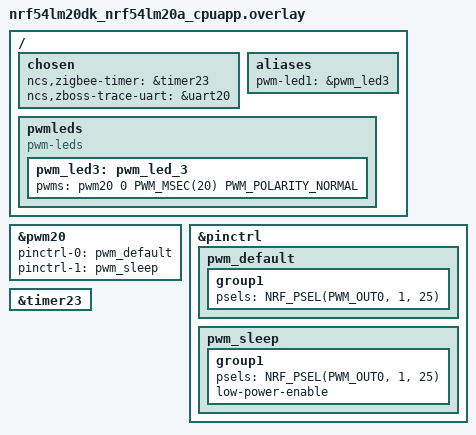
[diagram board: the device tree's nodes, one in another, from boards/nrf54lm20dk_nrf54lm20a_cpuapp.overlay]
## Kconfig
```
#
# Copyright (c) 2026 Nordic Semiconductor ASA
#
# SPDX-License-Identifier: LicenseRef-Nordic-5-Clause
#

# Sample configuration used for Thread networking
if OPENTHREAD

choice OPENTHREAD_NORDIC_LIBRARY_CONFIGURATION
	default OPENTHREAD_NORDIC_LIBRARY_FTD
endchoice

choice OPENTHREAD_DEVICE_TYPE
	default OPENTHREAD_FTD
endchoice

endif # OPENTHREAD

if CHIP
source "$(ZEPHYR_CONNECTEDHOMEIP_MODULE_DIR)/config/nrfconnect/chip-module/Kconfig.features"
source "$(ZEPHYR_CONNECTEDHOMEIP_MODULE_DIR)/config/nrfconnect/chip-module/Kconfig.defaults"
source "$(ZEPHYR_NRF_MODULE_DIR)/samples/matter/common/src/Kconfig"
endif

source "Kconfig.zephyr"
```

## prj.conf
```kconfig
#
# Copyright (c) 2024 Nordic Semiconductor ASA
#
# SPDX-License-Identifier: LicenseRef-Nordic-5-Clause
#

CONFIG_NCS_SAMPLES_DEFAULTS=y

CONFIG_UART_INTERRUPT_DRIVEN=y
CONFIG_SERIAL=y
CONFIG_GPIO=y
CONFIG_PWM=y

# Make sure printk is not printing to the UART console
CONFIG_CONSOLE=y
CONFIG_UART_CONSOLE=y

CONFIG_HEAP_MEM_POOL_SIZE=2048
CONFIG_MAIN_THREAD_PRIORITY=7

CONFIG_ZIGBEE_ADD_ON=y
CONFIG_ZIGBEE_APP_UTILS=y
CONFIG_ZIGBEE_ROLE_ROUTER=y

# Enable DK LED and Buttons library
CONFIG_DK_LIBRARY=y

# This example requires more workqueue stack
CONFIG_SYSTEM_WORKQUEUE_STACK_SIZE=2048

# Networking
CONFIG_NET_IPV6=n
CONFIG_NET_IP_ADDR_CHECK=n
CONFIG_NET_UDP=n

# Scene extension
CONFIG_ZIGBEE_SCENES=y

CONFIG_THREAD_MONITOR=y
CONFIG_THREAD_NAME=y
CONFIG_KERNEL_SHELL=y
```

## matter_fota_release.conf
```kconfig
#
# Copyright (c) 2026 Nordic Semiconductor ASA
#
# SPDX-License-Identifier: LicenseRef-Nordic-5-Clause
#
# Debug configuration for combined Zigbee + Matter + Thread (PoC)
# Includes logging, console, and debug features

#######################
# Release Optimizations
#######################

# Disable all debug features
CONFIG_USE_SEGGER_RTT=n
CONFIG_SHELL=n
CONFIG_OPENTHREAD_SHELL=n
CONFIG_CONSOLE=n
CONFIG_UART_CONSOLE=n
CONFIG_SERIAL=n
CONFIG_UART_INTERRUPT_DRIVEN=n
CONFIG_LOG=n
CONFIG_LOG_MODE_MINIMAL=n
CONFIG_ASSERT_VERBOSE=n
CONFIG_ASSERT_NO_FILE_INFO=y
CONFIG_PRINTK=n
CONFIG_PRINTK_SYNC=n
CONFIG_BOOT_BANNER=n

# Enable LTO to decrease the flash usage
CONFIG_LTO=y
CONFIG_ISR_TABLES_LOCAL_DECLARATION=y

# Additional size optimizations
CONFIG_SIZE_OPTIMIZATIONS=y
CONFIG_COMPILER_OPT="-Os"
```

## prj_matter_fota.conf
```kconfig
#
# Copyright (c) 2026 Nordic Semiconductor ASA
#
# SPDX-License-Identifier: LicenseRef-Nordic-5-Clause
#
# Debug configuration for combined Zigbee + Matter + Thread (PoC)
# Includes logging, console, and debug features

# Base sample configs
CONFIG_NCS_SAMPLES_DEFAULTS=y

CONFIG_UART_INTERRUPT_DRIVEN=y
CONFIG_SERIAL=y
CONFIG_GPIO=y
CONFIG_PWM=y

# Console
CONFIG_CONSOLE=y
CONFIG_UART_CONSOLE=y

# CONFIG_HEAP_MEM_POOL_SIZE=4096
CONFIG_MAIN_THREAD_PRIORITY=7

#######################
# Zigbee Configuration
#######################

CONFIG_ZIGBEE_ADD_ON=y
CONFIG_ZIGBEE_APP_UTILS=y
# Show Zigbee init/recovery logs (Device first start, network steering recovery).
CONFIG_ZIGBEE_APP_UTILS_LOG_LEVEL_INF=y
CONFIG_ZIGBEE_ROLE_ROUTER=y

# Scene extension
CONFIG_ZIGBEE_SCENES=y

# Enable DK LED and Buttons library
CONFIG_DK_LIBRARY=y

# This example requires more workqueue stack
CONFIG_SYSTEM_WORKQUEUE_STACK_SIZE=2048

CONFIG_ZBOSS_OSIF_LOG_LEVEL_INF=y

#######################
# Zigbee FOTA Configuration
#######################

# FIXME: Disabled Zigbee FOTA for initial development
# # Enable Zigbee FOTA library
# CONFIG_ZIGBEE_FOTA=y
# CONFIG_ZIGBEE_FOTA_HW_VERSION=52
# CONFIG_ZIGBEE_FOTA_ENDPOINT=5
# CONFIG_MCUBOOT_IMGTOOL_SIGN_VERSION="1.0.0"
# CONFIG_ZIGBEE_FOTA_COMMENT="light_bulb_matter"

# # Ensure an MCUboot-compatible binary is generated.
# CONFIG_IMG_MANAGER=y
# CONFIG_STREAM_FLASH=y
# CONFIG_DFU_TARGET_MCUBOOT=y
# CONFIG_IMG_ERASE_PROGRESSIVELY=y
# CONFIG_ZIGBEE_FOTA_PROGRESS_EVT=y

# # Increase the number of RX buffers for FOTA
# CONFIG_NRF_802154_RX_BUFFERS=32

#######################
# Matter Configuration
#######################

# Enable CHIP (Matter)
CONFIG_CHIP=y
CONFIG_CHIP_PROJECT_CONFIG="include/chip_project_config.h"
CONFIG_CHIP_DEVICE_PRODUCT_NAME="Matter Zigbee Light Bulb"

# Configure ZAP file
CONFIG_NCS_SAMPLE_MATTER_ZAP_FILE_PATH="${APPLICATION_CONFIG_DIR}/src/matter_zap/light_bulb.zap"

# 32773 == 0x8005 (example lighting-app)
CONFIG_CHIP_DEVICE_PRODUCT_ID=32773
CONFIG_STD_CPP17=y

# Enable Matter pairing automatically on application start.
CONFIG_CHIP_ENABLE_PAIRING_AUTOSTART=y

# Enable Matter extended announcement and increase duration to 1 hour.
CONFIG_CHIP_BLE_EXT_ADVERTISING=y
CONFIG_CHIP_BLE_ADVERTISING_DURATION=60

CONFIG_BT_DEVICE_NAME="MatterZigbee"

# Other settings
CONFIG_THREAD_NAME=y
CONFIG_MPU_STACK_GUARD=y
CONFIG_RESET_ON_FATAL_ERROR=n

# Reduce application size
CONFIG_USE_SEGGER_RTT=n

# FIXME: Disabled Factory Data feature for initial development
# CONFIG_CHIP_FACTORY_DATA_NONE=y

# FIXME: Disabled Matter OTA for initial development
CONFIG_CHIP_OTA_REQUESTOR=n
CONFIG_CHIP_BOOTLOADER_MCUBOOT=n
CONFIG_CHIP_BOOTLOADER_NONE=y

# Increase system workqueue stack for combined protocols (with Thread)
CONFIG_SYSTEM_WORKQUEUE_STACK_SIZE=6144

# Libc malloc arena required for Zigbee + Matter coexistence.
# - 0: no libc heap -> Matter init fails (malloc/calloc used during init).
# - -1: "all remaining RAM" -> on this build the computed heap extends past
#   valid RAM and triggers a precise data bus fault in sys_heap_init().
# - Positive value: static BSS heap of that size -> valid heap, no fault.
# Matter uses CHIP_MALLOC_SYS_HEAP for its own allocations; this arena
# covers libc malloc() used elsewhere (init, Zephyr, Zigbee, etc.).
CONFIG_COMMON_LIBC_MALLOC_ARENA_SIZE=-1

## PoC Configuration ##
# Note: This configuration links all three stacks (Zigbee, Thread, Matter) for memory estimation
# It will have runtime conflicts as Zigbee and Thread cannot share 802.15.4 radio simultaneously
# This is intentional - goal is to measure maximum memory footprint

# Keep Matter shell disabled to avoid getopt conflicts
CONFIG_CHIP_LIB_SHELL=n
CONFIG_NCS_SAMPLE_MATTER_TEST_SHELL=n

# Larger settings partition for Zigbee + Matter
CONFIG_PM_PARTITION_SIZE_SETTINGS_STORAGE=0x8000

# Enable for OpenThread logging
# UNCOMENT TO SEE LOGS FROM OPENTHREAD
# CONFIG_LOG_MODE_DEFERRED=y
# CONFIG_OPENTHREAD_DEBUG=y
# CONFIG_OPENTHREAD_LOG_LEVEL_DEBG=y
# CONFIG_LOG_BUFFER_SIZE=81920
# CONFIG_SHELL=y
# CONFIG_OPENTHREAD_SHELL=y

# Dispatcher 
CONFIG_NRF_802154_CALLBACKS_DISPATCHER=y

# We need it to disable ZBOSS thread
CONFIG_ZIGBEE_DEBUG_FUNCTIONS=y

# Must be a preemptible priority (0–15), not cooperative (-1). With -1, ZBOSS is
# coop priority -1 and is outranked by MPSL Work (prio -8), so it never runs.
# State 128 = _THREAD_QUEUED (runnable); ZBOSS stays queued and never gets CPU.
CONFIG_ZBOSS_DEFAULT_THREAD_PRIORITY=1
CONFIG_ZBOSS_DEFAULT_THREAD_STACK_SIZE=6144

# Switch to internal 802.15.4 radio source to fetch required changes.
CONFIG_NRF_802154_SOURCE_INTERNAL=y
```

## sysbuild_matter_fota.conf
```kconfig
#
# Copyright (c) 2026 Nordic Semiconductor ASA
#
# SPDX-License-Identifier: LicenseRef-Nordic-5-Clause
#

# Enable Matter support in sysbuild
SB_CONFIG_MATTER=y
SB_CONFIG_MATTER_FACTORY_DATA_GENERATE=y

# MCUBoot configuration
# SB_CONFIG_PM_OVERRIDE_EXTERNAL_DRIVER_CHECK=n
# SB_CONFIG_PM_EXTERNAL_FLASH_MCUBOOT_SECONDARY=n

SB_CONFIG_PARTITION_MANAGER=n

SB_CONFIG_MCUBOOT_MODE_OVERWRITE_ONLY=y
SB_CONFIG_MCUBOOT_COMPRESSED_IMAGE_SUPPORT=y
```

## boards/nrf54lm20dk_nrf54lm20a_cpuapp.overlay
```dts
/*
 * Copyright (c) 2025 Nordic Semiconductor ASA
 *
 * SPDX-License-Identifier: LicenseRef-Nordic-5-Clause
 */

#include <nrf54lm20_matter_zigbee_combined_partitions.dtsi>

/ {
	chosen {
		ncs,zigbee-timer = &timer23;
		ncs,zboss-trace-uart = &uart20;
	};

	aliases {
		/* Configure PWM module for led1 (LED2 on the board) */
		pwm-led1 = &pwm_led3;
	};

	pwmleds {
		compatible = "pwm-leds";
		pwm_led3: pwm_led_3 {
			pwms = <&pwm20 0 PWM_MSEC(20) PWM_POLARITY_NORMAL>;
		};
	};
};


&pwm20 {
	status = "okay";
	pinctrl-0 = <&pwm_default>;
	pinctrl-1 = <&pwm_sleep>;
	pinctrl-names = "default", "sleep";
};

&pinctrl {
	pwm_default: pwm_default {
		group1 {
			psels = <NRF_PSEL(PWM_OUT0, 1, 25)>;
		};
	};
	pwm_sleep: pwm_sleep {
		group1 {
			psels = <NRF_PSEL(PWM_OUT0, 1, 25)>;
			low-power-enable;
		};
	};
};

&timer23 {
	status = "okay";
};
```

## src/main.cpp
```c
/*
 * Copyright (c) 2024 Nordic Semiconductor ASA
 *
 * SPDX-License-Identifier: LicenseRef-Nordic-5-Clause
 */

/** @file
 *
 * @brief Simple Zigbee light bulb implementation.
 */

#include "app_task_zigbee.h"

#ifdef CONFIG_CHIP

#include "app_task.h"
#include <app/matter_event_handler.h>
#include <nrf_802154_callbacks_dispatcher.h>
#include <openthread.h>

extern "C" {
#include <zb_nrf_platform.h>
}

#include <zephyr/logging/log.h>

LOG_MODULE_REGISTER(app, CONFIG_CHIP_APP_LOG_LEVEL);

/* Zephyr thread stack size and priority */
#define ZIGBEE_THREAD_STACK_SIZE 2048
#define ZIGBEE_THREAD_PRIORITY 3
#define MATTER_THREAD_STACK_SIZE 3072
#define MATTER_THREAD_PRIORITY 3

namespace {

void zigbee_thread_fn() { ZigbeeStart(); }
void matter_thread_fn() { AppTask::Instance().StartApp(); }

K_THREAD_DEFINE(zigbee_thread_id, ZIGBEE_THREAD_STACK_SIZE, zigbee_thread_fn,
                NULL, NULL, NULL, ZIGBEE_THREAD_PRIORITY, 0, 0);

K_THREAD_DEFINE(matter_thread_id, MATTER_THREAD_STACK_SIZE, matter_thread_fn,
                NULL, NULL, NULL, MATTER_THREAD_PRIORITY, 0, 0);

void switch_to_thread_radio(void) {
  k_thread_abort(zigbee_thread_id);
  zigbee_deinit();
  int ret = nrf_802154_callbacks_dispatcher_switch("openthread");
  if (ret != 0) {
    LOG_ERR("Failed to switch 802.15.4 radio to Thread: %d", ret);
  }
}

void matter_zigbee_event_handler(
    const chip::DeviceLayer::ChipDeviceEvent *event, intptr_t arg) {
  switch (event->Type) {
  case chip::DeviceLayer::DeviceEventType::kSecureSessionEstablished:
    /* Switch to Thread Radio and disable Zigbee Stack*/
    if (!chip::DeviceLayer::ThreadStackMgr().IsThreadAttached()) {
      switch_to_thread_radio();
    }
    break;
  case chip::DeviceLayer::DeviceEventType::kFactoryReset:
    /* Remove also the zigbee stack data */
    zigbee_pibcache_pan_id_clear();
  default:
    break;
  }
}
} // namespace

#endif

int main(void) {

#ifdef CONFIG_CHIP

  int ret = nrf_802154_callbacks_dispatcher_switch("zigbee");
  if (ret != 0) {
    LOG_ERR("Failed to switch 802.15.4 radio to Zigbee: %d", ret);
  }

  // int ret = nrf_802154_callbacks_dispatcher_switch("openthread");
  // if (ret != 0) {
  //   LOG_ERR("Failed to switch 802.15.4 radio to Zigbee: %d", ret);
  // }
  // ret = nrf_802154_callbacks_dispatcher_switch("openthread");
  // if (ret != 0) {
  //   LOG_ERR("Failed to switch 802.15.4 radio to Zigbee: %d", ret);
  // }

  Nrf::Matter::RegisterEventHandler(matter_zigbee_event_handler, 0);

  k_thread_start(zigbee_thread_id);
  k_thread_start(matter_thread_id);

#else

  ZigbeeStart();

#endif

  return 0;
}
```

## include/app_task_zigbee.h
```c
/*
 * Copyright (c) 2024 Nordic Semiconductor ASA
 *
 * SPDX-License-Identifier: LicenseRef-Nordic-5-Clause
 */

 #ifndef APP_TASK_ZIGBEE_H
 #define APP_TASK_ZIGBEE_H 1
 
void ZigbeeStart(void);

 #endif /* APP_TASK_ZIGBEE_H */
 
```

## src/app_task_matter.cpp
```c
/*
 * Copyright (c) 2026 Nordic Semiconductor ASA
 *
 * SPDX-License-Identifier: LicenseRef-Nordic-5-Clause
 */

#include "app_task.h"

#include "app/matter_init.h"
#include "app/task_executor.h"

#if defined(CONFIG_PWM)
#include "pwm/pwm_device.h"
#endif

#include "clusters/identify.h"

#include <app-common/zap-generated/attributes/Accessors.h>
#include <app/persistence/AttributePersistenceProviderInstance.h>
#include <app/persistence/DefaultAttributePersistenceProvider.h>
#include <app/persistence/DeferredAttributePersistenceProvider.h>
#include <app/server/Server.h>
#include <setup_payload/OnboardingCodesUtil.h>

#include <zephyr/logging/log.h>

LOG_MODULE_DECLARE(app, CONFIG_CHIP_APP_LOG_LEVEL);

using namespace ::chip;
using namespace ::chip::app;
using namespace ::chip::DeviceLayer;

namespace
{
constexpr EndpointId kLightEndpointId = 1;
constexpr uint8_t kDefaultMinLevel = 0;
constexpr uint8_t kDefaultMaxLevel = 254;

Nrf::Matter::IdentifyCluster sIdentifyCluster(kLightEndpointId, true, []() {
	Nrf::PostTask([] { Nrf::GetBoard().GetLED(Nrf::DeviceLeds::LED2).Set(false); });
#if defined(CONFIG_PWM)
	Nrf::PostTask([] { AppTask::Instance().GetPWMDevice().ApplyLevel(); });
#endif
});

#if defined(CONFIG_PWM)
const struct pwm_dt_spec sLightPwmDevice = PWM_DT_SPEC_GET(DT_ALIAS(pwm_led1));
#endif

/* Define a custom attribute persister which makes actual write of the CurrentLevel attribute value
 * to the non-volatile storage only when it has remained constant for 5 seconds. This is to reduce
 * the flash wearout when the attribute changes frequently as a result of MoveToLevel command.
 * DeferredAttribute object describes a deferred attribute, but also holds a buffer with a value to
 * be written, so it must live so long as the DeferredAttributePersistenceProvider object.
 */
DeferredAttribute gCurrentLevelPersister(ConcreteAttributePath(kLightEndpointId, Clusters::LevelControl::Id,
							       Clusters::LevelControl::Attributes::CurrentLevel::Id));

/* Deferred persistence will be auto-initialized as soon as the default persistence is initialized */
DefaultAttributePersistenceProvider gSimpleAttributePersistence;
DeferredAttributePersistenceProvider gDeferredAttributePersister(gSimpleAttributePersistence,
								 Span<DeferredAttribute>(&gCurrentLevelPersister, 1),
								 System::Clock::Milliseconds32(5000));

#define APPLICATION_BUTTON_MASK DK_BTN2_MSK
} /* namespace */

void AppTask::LightingActionEventHandler(const LightingEvent &event)
{
#if defined(CONFIG_PWM)
	Nrf::PWMDevice::Action_t action = Nrf::PWMDevice::INVALID_ACTION;
	int32_t actor = 0;
	if (event.Actor == LightingActor::Button) {
		action = Instance().mPWMDevice.IsTurnedOn() ? Nrf::PWMDevice::OFF_ACTION : Nrf::PWMDevice::ON_ACTION;
		actor = static_cast<int32_t>(event.Actor);
	}

	if (action == Nrf::PWMDevice::INVALID_ACTION || !Instance().mPWMDevice.InitiateAction(action, actor, NULL)) {
		LOG_INF("An action could not be initiated.");
	}
#else
	Nrf::GetBoard().GetLED(Nrf::DeviceLeds::LED2).Set(!Nrf::GetBoard().GetLED(Nrf::DeviceLeds::LED2).GetState());
#endif
}

void AppTask::ButtonEventHandler(Nrf::ButtonState state, Nrf::ButtonMask hasChanged)
{
	if ((APPLICATION_BUTTON_MASK & hasChanged) & state) {
		Nrf::PostTask([] {
			LightingEvent event;
			event.Actor = LightingActor::Button;
			LightingActionEventHandler(event);
		});
	}
}

#if defined(CONFIG_PWM)
void AppTask::ActionInitiated(Nrf::PWMDevice::Action_t action, int32_t actor)
{
	if (action == Nrf::PWMDevice::ON_ACTION) {
		LOG_INF("Turn On Action has been initiated");
	} else if (action == Nrf::PWMDevice::OFF_ACTION) {
		LOG_INF("Turn Off Action has been initiated");
	} else if (action == Nrf::PWMDevice::LEVEL_ACTION) {
		LOG_INF("Level Action has been initiated");
	}
}

void AppTask::ActionCompleted(Nrf::PWMDevice::Action_t action, int32_t actor)
{
	if (action == Nrf::PWMDevice::ON_ACTION) {
		LOG_INF("Turn On Action has been completed");
	} else if (action == Nrf::PWMDevice::OFF_ACTION) {
		LOG_INF("Turn Off Action has been completed");
	} else if (action == Nrf::PWMDevice::LEVEL_ACTION) {
		LOG_INF("Level Action has been completed");
	}

	if (actor == static_cast<int32_t>(LightingActor::Button)) {
		Instance().UpdateClusterState();
	}
}
#endif /* CONFIG_PWM */

void AppTask::UpdateClusterState()
{
	SystemLayer().ScheduleLambda([this] {
#if defined(CONFIG_PWM)
		/* write the new on/off value */
		Protocols::InteractionModel::Status status =
			Clusters::OnOff::Attributes::OnOff::Set(kLightEndpointId, mPWMDevice.IsTurnedOn());
#else
		Protocols::InteractionModel::Status status = Clusters::OnOff::Attributes::OnOff::Set(
			kLightEndpointId, Nrf::GetBoard().GetLED(Nrf::DeviceLeds::LED2).GetState());
#endif
		if (status != Protocols::InteractionModel::Status::Success) {
			LOG_ERR("Updating on/off cluster failed: %x", to_underlying(status));
		}

#if defined(CONFIG_PWM)
		/* write the current level */
		status = Clusters::LevelControl::Attributes::CurrentLevel::Set(kLightEndpointId, mPWMDevice.GetLevel());
#else
		/* write the current level */
		if (Nrf::GetBoard().GetLED(Nrf::DeviceLeds::LED2).GetState()) {
			status = Clusters::LevelControl::Attributes::CurrentLevel::Set(kLightEndpointId, 100);
		} else {
			status = Clusters::LevelControl::Attributes::CurrentLevel::Set(kLightEndpointId, 0);
		}
#endif

		if (status != Protocols::InteractionModel::Status::Success) {
			LOG_ERR("Updating level cluster failed: %x", to_underlying(status));
		}
	});
}

void AppTask::InitPWMDDevice()
{
#if defined(CONFIG_PWM)
	/* Initialize lighting device (PWM) */
	uint8_t minLightLevel = kDefaultMinLevel;
	Clusters::LevelControl::Attributes::MinLevel::Get(kLightEndpointId, &minLightLevel);

	uint8_t maxLightLevel = kDefaultMaxLevel;
	Clusters::LevelControl::Attributes::MaxLevel::Get(kLightEndpointId, &maxLightLevel);

	Clusters::LevelControl::Attributes::CurrentLevel::TypeInfo::Type currentLevel;
	Clusters::LevelControl::Attributes::CurrentLevel::Get(kLightEndpointId, currentLevel);

	int ret =
		mPWMDevice.Init(&sLightPwmDevice, minLightLevel, maxLightLevel, currentLevel.ValueOr(kDefaultMaxLevel));
	if (ret != 0) {
		LOG_ERR("Failed to initialize PWD device.");
	}

	mPWMDevice.SetCallbacks(ActionInitiated, ActionCompleted);
#endif
}

CHIP_ERROR AppTask::Init()
{
	/* Initialize Matter stack */
	ReturnErrorOnFailure(Nrf::Matter::PrepareServer(Nrf::Matter::InitData{ .mPostServerInitClbk = []() {
		app::SetAttributePersistenceProvider(&gDeferredAttributePersister);
		gSimpleAttributePersistence.Init(Nrf::Matter::GetPersistentStorageDelegate());
		return CHIP_NO_ERROR;
	} }));

	if (!Nrf::GetBoard().Init(ButtonEventHandler)) {
		LOG_ERR("User interface initialization failed.");
		return CHIP_ERROR_INCORRECT_STATE;
	}

	/* Register Matter event handler that controls the connectivity status LED based on the captured Matter network
	 * state. */
	ReturnErrorOnFailure(Nrf::Matter::RegisterEventHandler(Nrf::Board::DefaultMatterEventHandler, 0));

	ReturnErrorOnFailure(sIdentifyCluster.Init());

	return Nrf::Matter::StartServer();
}

CHIP_ERROR AppTask::StartApp()
{
	ReturnErrorOnFailure(Init());

	while (true) {
		Nrf::DispatchNextTask();
	}

	return CHIP_NO_ERROR;
}
```

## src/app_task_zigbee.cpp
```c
/*
 * Copyright (c) 2026 Nordic Semiconductor ASA
 *
 * SPDX-License-Identifier: LicenseRef-Nordic-5-Clause
 */

/** @file
 *
 * @brief Simple Zigbee light bulb implementation.
 */

#include <soc.h>
#include <zephyr/device.h>
#include <zephyr/drivers/pwm.h>
#include <zephyr/kernel.h>
#include <zephyr/logging/log.h>
#include <zephyr/settings/settings.h>
#include <zephyr/types.h>

extern "C" {
#include "zb_dimmable_light.h"
#include <dk_buttons_and_leds.h>
#include <zb_mem_config_med.h>
#include <zb_nrf_platform.h>
#include <zboss_api.h>
#include <zboss_api_addons.h>
#include <zboss_api_zcl.h>
#include <zboss_api_zdo.h>
#include <zigbee/zigbee_app_utils.h>
#include <zigbee/zigbee_error_handler.h>
#include <zigbee/zigbee_zcl_scenes.h>
}

#define RUN_STATUS_LED DK_LED1
#define RUN_LED_BLINK_INTERVAL 1000

/* Device endpoint, used to receive light controlling commands. */
#define DIMMABLE_LIGHT_ENDPOINT 10

/* Version of the application software (1 byte). */
#define BULB_INIT_BASIC_APP_VERSION 01

/* Version of the implementation of the Zigbee stack (1 byte). */
#define BULB_INIT_BASIC_STACK_VERSION 10

/* Version of the hardware of the device (1 byte). */
#define BULB_INIT_BASIC_HW_VERSION 11

/* Manufacturer name (32 bytes). */
#define BULB_INIT_BASIC_MANUF_NAME "Nordic"

/* Model number assigned by manufacturer (32-bytes long string). */
#define BULB_INIT_BASIC_MODEL_ID "Dimable_Light_v0.1"

/* First 8 bytes specify the date of manufacturer of the device
 * in ISO 8601 format (YYYYMMDD). The rest (8 bytes) are manufacturer specific.
 */
#define BULB_INIT_BASIC_DATE_CODE "20200329"

/* Type of power sources available for the device.
 * For possible values see section 3.2.2.2.8 of ZCL specification.
 */
#define BULB_INIT_BASIC_POWER_SOURCE ZB_ZCL_BASIC_POWER_SOURCE_DC_SOURCE

/* Describes the physical location of the device (16 bytes).
 * May be modified during commissioning process.
 */
#define BULB_INIT_BASIC_LOCATION_DESC "Office desk"

/* Describes the type of physical environment.
 * For possible values see section 3.2.2.2.10 of ZCL specification.
 */
#define BULB_INIT_BASIC_PH_ENV ZB_ZCL_BASIC_ENV_UNSPECIFIED

/* LED indicating that light switch successfully joind Zigbee network. */
#define ZIGBEE_NETWORK_STATE_LED DK_LED3

/* LED immitaing dimmable light bulb - define for informational
 * purposes only.
 */
#define BULB_LED DK_LED4

/* Button used to enter the Bulb into the Identify mode. */
#define IDENTIFY_MODE_BUTTON DK_BTN4_MSK

/* Use onboard led4 to act as a light bulb.
 * The app.overlay file has this at node label "pwm_led3" in /pwmleds.
 */
#define PWM_DK_LED_NODE DT_NODELABEL(pwm_led3)

#if DT_NODE_HAS_STATUS(PWM_DK_LED_NODE, okay)
static const struct pwm_dt_spec led_pwm = PWM_DT_SPEC_GET(PWM_DK_LED_NODE);
#else
#error "Choose supported PWM driver"
#endif

/* Led PWM period, calculated for 100 Hz signal - in microseconds. */
#define LED_PWM_PERIOD_US (USEC_PER_SEC / 100U)

#ifndef ZB_ROUTER_ROLE
#error Define ZB_ROUTER_ROLE to compile router source code.
#endif

/* Button to start Factory Reset */
#define FACTORY_RESET_BUTTON IDENTIFY_MODE_BUTTON

LOG_MODULE_REGISTER(app, LOG_LEVEL_INF);

/* Main application customizable context.
 * Stores all settings and static values.
 */
typedef struct {
  zb_zcl_basic_attrs_ext_t basic_attr;
  zb_zcl_identify_attrs_t identify_attr;
  zb_zcl_scenes_attrs_t scenes_attr;
  zb_zcl_groups_attrs_t groups_attr;
  zb_zcl_on_off_attrs_t on_off_attr;
  zb_zcl_level_control_attrs_t level_control_attr;
} bulb_device_ctx_t;

/* Zigbee device application context storage. */
static bulb_device_ctx_t dev_ctx;

ZB_ZCL_DECLARE_IDENTIFY_ATTRIB_LIST(identify_attr_list,
                                    &dev_ctx.identify_attr.identify_time);

ZB_ZCL_DECLARE_GROUPS_ATTRIB_LIST(groups_attr_list,
                                  &dev_ctx.groups_attr.name_support);

ZB_ZCL_DECLARE_SCENES_ATTRIB_LIST(scenes_attr_list,
                                  &dev_ctx.scenes_attr.scene_count,
                                  &dev_ctx.scenes_attr.current_scene,
                                  &dev_ctx.scenes_attr.current_group,
                                  &dev_ctx.scenes_attr.scene_valid,
                                  &dev_ctx.scenes_attr.name_support);

ZB_ZCL_DECLARE_BASIC_ATTRIB_LIST_EXT(
    basic_attr_list, &dev_ctx.basic_attr.zcl_version,
    &dev_ctx.basic_attr.app_version, &dev_ctx.basic_attr.stack_version,
    &dev_ctx.basic_attr.hw_version, dev_ctx.basic_attr.mf_name,
    dev_ctx.basic_attr.model_id, dev_ctx.basic_attr.date_code,
    &dev_ctx.basic_attr.power_source, dev_ctx.basic_attr.location_id,
    &dev_ctx.basic_attr.ph_env, dev_ctx.basic_attr.sw_ver);

/* On/Off cluster attributes additions data */
ZB_ZCL_DECLARE_ON_OFF_ATTRIB_LIST(on_off_attr_list,
                                  &dev_ctx.on_off_attr.on_off);

ZB_ZCL_DECLARE_LEVEL_CONTROL_ATTRIB_LIST(
    level_control_attr_list, &dev_ctx.level_control_attr.current_level,
    &dev_ctx.level_control_attr.remaining_time);

ZB_DECLARE_DIMMABLE_LIGHT_CLUSTER_LIST(dimmable_light_clusters, basic_attr_list,
                                       identify_attr_list, groups_attr_list,
                                       scenes_attr_list, on_off_attr_list,
                                       level_control_attr_list);

ZB_DECLARE_DIMMABLE_LIGHT_EP(dimmable_light_ep, DIMMABLE_LIGHT_ENDPOINT,
                             dimmable_light_clusters);

ZBOSS_DECLARE_DEVICE_CTX_1_EP(dimmable_light_ctx, dimmable_light_ep);

/**@brief Starts identifying the device.
 *
 * @param  bufid  Unused parameter, required by ZBOSS scheduler API.
 */
static void start_identifying(zb_bufid_t bufid) {
  ZVUNUSED(bufid);

  if (ZB_JOINED()) {
    /* Check if endpoint is in identifying mode,
     * if not, put desired endpoint in identifying mode.
     */
    if (dev_ctx.identify_attr.identify_time ==
        ZB_ZCL_IDENTIFY_IDENTIFY_TIME_DEFAULT_VALUE) {

      zb_ret_t zb_err_code =
          zb_bdb_finding_binding_target(DIMMABLE_LIGHT_ENDPOINT);

      if (zb_err_code == RET_OK) {
        LOG_INF("Enter identify mode");
      } else if (zb_err_code == RET_INVALID_STATE) {
        LOG_WRN("RET_INVALID_STATE - Cannot enter identify mode");
      } else {
        ZB_ERROR_CHECK(zb_err_code);
      }
    } else {
      LOG_INF("Cancel identify mode");
      zb_bdb_finding_binding_target_cancel();
    }
  } else {
    LOG_WRN("Device not in a network - cannot enter identify mode");
  }
}

/**@brief Callback for button events.
 *
 * @param[in]   button_state  Bitmask containing the state of the buttons.
 * @param[in]   has_changed   Bitmask containing buttons that have changed their
 * state.
 */
static void button_changed(uint32_t button_state, uint32_t has_changed) {
  if (IDENTIFY_MODE_BUTTON & has_changed) {
    if (IDENTIFY_MODE_BUTTON & button_state) {
      /* Button changed its state to pressed */
    } else {
      /* Button changed its state to released */
      if (was_factory_reset_done()) {
        /* The long press was for Factory Reset */
        LOG_DBG("After Factory Reset - ignore button release");
      } else {
        /* Button released before Factory Reset */

        /* Start identification mode */
        ZB_SCHEDULE_APP_CALLBACK(start_identifying, 0);
      }
    }
  }

  check_factory_reset_button(button_state, has_changed);
}

/**@brief Function for initializing additional PWM leds. */
static void pwm_led_init(void) {
  if (!device_is_ready(led_pwm.dev)) {
    LOG_ERR("Error: PWM device %s is not ready", led_pwm.dev->name);
  }
}

/**@brief Function for initializing LEDs and Buttons. */
static void configure_gpio(void) {
  int err;

  err = dk_buttons_init(button_changed);
  if (err) {
    LOG_ERR("Cannot init buttons (err: %d)", err);
  }

  err = dk_leds_init();
  if (err) {
    LOG_ERR("Cannot init LEDs (err: %d)", err);
  }

  pwm_led_init();
}

/**@brief Sets brightness of bulb luminous executive element
 *
 * @param[in] brightness_level Brightness level, allowed values 0 ... 255,
 *                             0 - turn off, 255 - full brightness.
 */
static void light_bulb_set_brightness(zb_uint8_t brightness_level) {
  uint32_t pulse = brightness_level * LED_PWM_PERIOD_US / 255U;

  if (pwm_set_dt(&led_pwm, PWM_USEC(LED_PWM_PERIOD_US), PWM_USEC(pulse))) {
    LOG_ERR("Pwm led 4 set fails:\n");
    return;
  }
}

/**@brief Function for setting the light bulb brightness.
 *
 * @param[in] new_level   Light bulb brightness value.
 */
static void level_control_set_value(zb_uint16_t new_level) {
  LOG_INF("Set level value: %i", new_level);

  ZB_ZCL_SET_ATTRIBUTE(DIMMABLE_LIGHT_ENDPOINT, ZB_ZCL_CLUSTER_ID_LEVEL_CONTROL,
                       ZB_ZCL_CLUSTER_SERVER_ROLE,
                       ZB_ZCL_ATTR_LEVEL_CONTROL_CURRENT_LEVEL_ID,
                       (zb_uint8_t *)&new_level, ZB_FALSE);

  light_bulb_set_brightness(new_level);
}

/**@brief Function for turning ON/OFF the light bulb.
 *
 * @param[in]   on   Boolean light bulb state.
 */
static void on_off_set_value(zb_bool_t on) {
  LOG_INF("Set ON/OFF value: %i", on);

  ZB_ZCL_SET_ATTRIBUTE(DIMMABLE_LIGHT_ENDPOINT, ZB_ZCL_CLUSTER_ID_ON_OFF,
                       ZB_ZCL_CLUSTER_SERVER_ROLE, ZB_ZCL_ATTR_ON_OFF_ON_OFF_ID,
                       (zb_uint8_t *)&on, ZB_FALSE);

  if (on) {
    light_bulb_set_brightness(dev_ctx.level_control_attr.current_level);
  } else {
    light_bulb_set_brightness(0U);
  }
}

/**@brief Function to toggle the identify LED - BULB_LED is used for this.
 *
 * @param  bufid  Unused parameter, required by ZBOSS scheduler API.
 */
static void toggle_identify_led(zb_bufid_t bufid) {
  static int blink_status;

  light_bulb_set_brightness(((++blink_status) % 2) ? (255U) : (0U));
  ZB_SCHEDULE_APP_ALARM(toggle_identify_led, bufid,
                        ZB_MILLISECONDS_TO_BEACON_INTERVAL(100));
}

/**@brief Function to handle identify notification events on the first endpoint.
 *
 * @param  bufid  Unused parameter, required by ZBOSS scheduler API.
 */
static void identify_cb(zb_bufid_t bufid) {
  zb_ret_t zb_err_code;

  if (bufid) {
    /* Schedule a self-scheduling function that will toggle the LED. */
    ZB_SCHEDULE_APP_CALLBACK(toggle_identify_led, bufid);
  } else {
    /* Cancel the toggling function alarm and restore current Zigbee LED state.
     */
    zb_err_code =
        ZB_SCHEDULE_APP_ALARM_CANCEL(toggle_identify_led, ZB_ALARM_ANY_PARAM);
    ZVUNUSED(zb_err_code);

    if (dev_ctx.on_off_attr.on_off) {
      light_bulb_set_brightness(dev_ctx.level_control_attr.current_level);
    } else {
      light_bulb_set_brightness(0U);
    }
  }
}

/**@brief Function for initializing all clusters attributes.
 */
static void bulb_clusters_attr_init(void) {
  /* Basic cluster attributes data */
  dev_ctx.basic_attr.zcl_version = ZB_ZCL_VERSION;
  dev_ctx.basic_attr.app_version = BULB_INIT_BASIC_APP_VERSION;
  dev_ctx.basic_attr.stack_version = BULB_INIT_BASIC_STACK_VERSION;
  dev_ctx.basic_attr.hw_version = BULB_INIT_BASIC_HW_VERSION;

  /* Use ZB_ZCL_SET_STRING_VAL to set strings, because the first byte
   * should contain string length without trailing zero.
   *
   * For example "test" string will be encoded as:
   *   [(0x4), 't', 'e', 's', 't']
   */
  ZB_ZCL_SET_STRING_VAL(dev_ctx.basic_attr.mf_name, BULB_INIT_BASIC_MANUF_NAME,
                        ZB_ZCL_STRING_CONST_SIZE(BULB_INIT_BASIC_MANUF_NAME));

  ZB_ZCL_SET_STRING_VAL(dev_ctx.basic_attr.model_id, BULB_INIT_BASIC_MODEL_ID,
                        ZB_ZCL_STRING_CONST_SIZE(BULB_INIT_BASIC_MODEL_ID));

  ZB_ZCL_SET_STRING_VAL(dev_ctx.basic_attr.date_code, BULB_INIT_BASIC_DATE_CODE,
                        ZB_ZCL_STRING_CONST_SIZE(BULB_INIT_BASIC_DATE_CODE));

  dev_ctx.basic_attr.power_source = BULB_INIT_BASIC_POWER_SOURCE;

  ZB_ZCL_SET_STRING_VAL(
      dev_ctx.basic_attr.location_id, BULB_INIT_BASIC_LOCATION_DESC,
      ZB_ZCL_STRING_CONST_SIZE(BULB_INIT_BASIC_LOCATION_DESC));

  dev_ctx.basic_attr.ph_env = BULB_INIT_BASIC_PH_ENV;

  /* Identify cluster attributes data. */
  dev_ctx.identify_attr.identify_time =
      ZB_ZCL_IDENTIFY_IDENTIFY_TIME_DEFAULT_VALUE;

  /* On/Off cluster attributes data. */
  dev_ctx.on_off_attr.on_off = (zb_bool_t)ZB_ZCL_ON_OFF_IS_ON;

  dev_ctx.level_control_attr.current_level =
      ZB_ZCL_LEVEL_CONTROL_LEVEL_MAX_VALUE;
  dev_ctx.level_control_attr.remaining_time =
      ZB_ZCL_LEVEL_CONTROL_REMAINING_TIME_DEFAULT_VALUE;

  ZB_ZCL_SET_ATTRIBUTE(DIMMABLE_LIGHT_ENDPOINT, ZB_ZCL_CLUSTER_ID_ON_OFF,
                       ZB_ZCL_CLUSTER_SERVER_ROLE, ZB_ZCL_ATTR_ON_OFF_ON_OFF_ID,
                       (zb_uint8_t *)&dev_ctx.on_off_attr.on_off, ZB_FALSE);

  ZB_ZCL_SET_ATTRIBUTE(
      DIMMABLE_LIGHT_ENDPOINT, ZB_ZCL_CLUSTER_ID_LEVEL_CONTROL,
      ZB_ZCL_CLUSTER_SERVER_ROLE, ZB_ZCL_ATTR_LEVEL_CONTROL_CURRENT_LEVEL_ID,
      (zb_uint8_t *)&dev_ctx.level_control_attr.current_level, ZB_FALSE);
}

/**@brief Callback function for handling ZCL commands.
 *
 * @param[in]   bufid   Reference to Zigbee stack buffer
 *                      used to pass received data.
 */
static void zcl_device_cb(zb_bufid_t bufid) {
  zb_uint8_t cluster_id;
  zb_uint8_t attr_id;
  zb_zcl_device_callback_param_t *device_cb_param =
      ZB_BUF_GET_PARAM(bufid, zb_zcl_device_callback_param_t);

  LOG_INF("%s id %hd", __func__, device_cb_param->device_cb_id);

  /* Set default response value. */
  device_cb_param->status = RET_OK;

  switch (device_cb_param->device_cb_id) {
  case ZB_ZCL_LEVEL_CONTROL_SET_VALUE_CB_ID:
    LOG_INF("Level control setting to %d",
            device_cb_param->cb_param.level_control_set_value_param.new_value);
    level_control_set_value(
        device_cb_param->cb_param.level_control_set_value_param.new_value);
    break;

  case ZB_ZCL_SET_ATTR_VALUE_CB_ID:
    cluster_id = device_cb_param->cb_param.set_attr_value_param.cluster_id;
    attr_id = device_cb_param->cb_param.set_attr_value_param.attr_id;

    if (cluster_id == ZB_ZCL_CLUSTER_ID_ON_OFF) {
      uint8_t value =
          device_cb_param->cb_param.set_attr_value_param.values.data8;

      LOG_INF("on/off attribute setting to %hd", value);
      if (attr_id == ZB_ZCL_ATTR_ON_OFF_ON_OFF_ID) {
        on_off_set_value((zb_bool_t)value);
      }
    } else if (cluster_id == ZB_ZCL_CLUSTER_ID_LEVEL_CONTROL) {
      uint16_t value =
          device_cb_param->cb_param.set_attr_value_param.values.data16;

      LOG_INF("level control attribute setting to %hd", value);
      if (attr_id == ZB_ZCL_ATTR_LEVEL_CONTROL_CURRENT_LEVEL_ID) {
        level_control_set_value(value);
      }
    } else {
      /* Other clusters can be processed here */
      LOG_INF("Unhandled cluster attribute id: %d", cluster_id);
      device_cb_param->status = RET_NOT_IMPLEMENTED;
    }
    break;

  default:
    if (zcl_scenes_cb(bufid) == ZB_FALSE) {
      device_cb_param->status = RET_NOT_IMPLEMENTED;
    }
    break;
  }

  LOG_INF("%s status: %hd", __func__, device_cb_param->status);
}

/**@brief Zigbee stack event handler.
 *
 * @param[in]   bufid   Reference to the Zigbee stack buffer
 *                      used to pass signal.
 */
void zboss_signal_handler(zb_bufid_t bufid) {
  /* Update network status LED. */
  zigbee_led_status_update(bufid, ZIGBEE_NETWORK_STATE_LED);

#if defined(CONFIG_ZIGBEE_TOUCHLINK_TARGET)
  zigbee_touchlink_target_signal_handler(bufid);
#endif

  ZB_ERROR_CHECK(zigbee_default_signal_handler(bufid));

  /* All callbacks should either reuse or free passed buffers.
   * If bufid == 0, the buffer is invalid (not passed).
   */
  if (bufid) {
    zb_buf_free(bufid);
  }
}

int ZigbeeStart(void) {
  int blink_status = 0;
  int err;

  LOG_INF("Starting Zigbee R23 Light Bulb example");

  /* Initialize */
  configure_gpio();
  err = settings_subsys_init();
  if (err) {
    LOG_ERR("settings initialization failed");
  }
  register_factory_reset_button(FACTORY_RESET_BUTTON);

  /* Register callback for handling ZCL commands. */
  ZB_ZCL_REGISTER_DEVICE_CB(zcl_device_cb);

  /* Register dimmer switch device context (endpoints). */
  ZB_AF_REGISTER_DEVICE_CTX(&dimmable_light_ctx);

  bulb_clusters_attr_init();
  level_control_set_value(dev_ctx.level_control_attr.current_level);

  /* Register handler to identify notifications. */
  ZB_AF_SET_IDENTIFY_NOTIFICATION_HANDLER(DIMMABLE_LIGHT_ENDPOINT, identify_cb);

  /* Initialize ZCL scene table */
  zcl_scenes_init();

  /* Settings should be loaded after zcl_scenes_init */
  err = settings_load();
  if (err) {
    LOG_ERR("settings loading failed");
  }

  /* Start Zigbee default thread */
  zigbee_enable();

  LOG_INF("Zigbee R23 Light Bulb example started");

  while (1) {
    dk_set_led(RUN_STATUS_LED, (++blink_status) % 2);
    k_sleep(K_MSEC(RUN_LED_BLINK_INTERVAL));
  }
}
```

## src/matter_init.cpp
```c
/*
 * Copyright (c) 2026 Nordic Semiconductor ASA
 *
 * SPDX-License-Identifier: LicenseRef-Nordic-5-Clause
 */

#include <zephyr/kernel.h>
#include <zephyr/logging/log.h>

#ifdef CONFIG_CHIP

#include <DeviceInfoProviderImpl.h>
#include <app/clusters/network-commissioning/network-commissioning.h>
#include <app/server/Server.h>
#include <credentials/DeviceAttestationCredsProvider.h>
#include <credentials/examples/DeviceAttestationCredsExample.h>
#include <data-model-providers/codegen/Instance.h>
#include <platform/CHIPDeviceLayer.h>
#include <platform/OpenThread/GenericNetworkCommissioningThreadDriver.h>
#include <platform/nrfconnect/DeviceInstanceInfoProviderImpl.h>
#include <setup_payload/OnboardingCodesUtil.h>

#ifdef CONFIG_CHIP_CRYPTO_PSA
#include <crypto/PSAOperationalKeystore.h>
#endif

LOG_MODULE_REGISTER(matter_init, CONFIG_CHIP_APP_LOG_LEVEL);

using namespace ::chip;
using namespace ::chip::DeviceLayer;
using namespace ::chip::Credentials;

chip::app::Clusters::NetworkCommissioning::InstanceAndDriver<
    NetworkCommissioning::GenericThreadDriver>
    sThreadNetworkDriver(0 /*endpointId*/);
static chip::CommonCaseDeviceServerInitParams sServerInitParamsDefault;
static chip::DeviceLayer::DeviceInfoProviderImpl sDeviceInfoProviderDefault;

#ifdef CONFIG_CHIP_CRYPTO_PSA
static chip::Crypto::PSAOperationalKeystore sOperationalKeystoreDefault;
#endif

CHIP_ERROR configure_thread_role() {
  using ThreadRole = ConnectivityManager::ThreadDeviceType;

  ThreadRole threadRole{ThreadRole::kThreadDeviceType_MinimalEndDevice};
#ifdef CONFIG_OPENTHREAD_MTD_SED
#ifdef CONFIG_CHIP_THREAD_SSED
  threadRole = ThreadRole::kThreadDeviceType_SynchronizedSleepyEndDevice;
#else
  threadRole = ThreadRole::kThreadDeviceType_SleepyEndDevice;
#endif /* CONFIG_CHIP_THREAD_SSED */
#elif defined(CONFIG_OPENTHREAD_FTD)
  threadRole = ThreadRole::kThreadDeviceType_Router;
#endif /* CONFIG_OPENTHREAD_MTD_SED */

  return ConnectivityMgr().SetThreadDeviceType(threadRole);
}

void lock_open_thread_task(void) {
  chip::DeviceLayer::ThreadStackMgr().LockThreadStack();
}

void unlock_open_thread_task(void) {
  chip::DeviceLayer::ThreadStackMgr().UnlockThreadStack();
}

/**
 * @brief Initialize Matter stack for combined Zigbee+Matter application
 *
 * Simplified initialization for memory estimation purposes.
 * Full Zigbee/Matter integration would require additional synchronization.
 */
extern "C" int matter_init(void) {
  CHIP_ERROR err = CHIP_NO_ERROR;

  LOG_INF("Initializing Matter stack (simplified for memory estimation)");

  // Initialize Matter platform
  err = PlatformMgr().InitChipStack();
  if (err != CHIP_NO_ERROR) {
    LOG_ERR("PlatformMgr().InitChipStack() failed: %s", ErrorStr(err));
    return -ENODEV;
  }

  err = ThreadStackMgr().InitThreadStack();
  if (err != CHIP_NO_ERROR) {
    LOG_ERR("ThreadStackMgr().InitThreadStack() failed: %s", ErrorStr(err));
    return -ENODEV;
  }

  err = configure_thread_role();
  if (err != CHIP_NO_ERROR) {
    LOG_ERR("configure_thread_role() failed: %s", ErrorStr(err));
    return -ENODEV;
  }

  sThreadNetworkDriver.Init();

  // Initialize device attestation credentials
  SetDeviceInstanceInfoProvider(&DeviceInstanceInfoProviderMgrImpl());
  SetDeviceAttestationCredentialsProvider(Examples::GetExampleDACProvider());

  chip::Inet::EndPointStateOpenThread::OpenThreadEndpointInitParam nativeParams;
  nativeParams.lockCb = lock_open_thread_task;
  nativeParams.unlockCb = unlock_open_thread_task;
  nativeParams.openThreadInstancePtr =
      chip::DeviceLayer::ThreadStackMgrImpl().OTInstance();
  sServerInitParamsDefault.endpointNativeParams =
      static_cast<void *>(&nativeParams);

#ifdef CONFIG_CHIP_CRYPTO_PSA
  sServerInitParamsDefault.operationalKeystore = &sOperationalKeystoreDefault;
#endif

  sServerInitParamsDefault.InitializeStaticResourcesBeforeServerInit();

  SetDeviceInfoProvider(&sDeviceInfoProviderDefault);

  sServerInitParamsDefault.dataModelProvider =
      chip::app::CodegenDataModelProviderInstance(
          sServerInitParamsDefault.persistentStorageDelegate);

  err = Server::GetInstance().Init(sServerInitParamsDefault);
  if (err != CHIP_NO_ERROR) {
    LOG_ERR("Server::GetInstance().Init() failed: %s", ErrorStr(err));
    return -ENODEV;
  }

  ConfigurationMgr().LogDeviceConfig();
  PrintOnboardingCodes(
      RendezvousInformationFlags(chip::RendezvousInformationFlag::kBLE));

  // Start Matter event loop
  err = PlatformMgr().StartEventLoopTask();
  if (err != CHIP_NO_ERROR) {
    LOG_ERR("PlatformMgr().StartEventLoopTask() failed: %s", ErrorStr(err));
    return -ENODEV;
  }

  LOG_INF("Matter stack initialized successfully");

  return 0;
}

/**
 * @brief Synchronize Zigbee and Matter light states
 *
 * Simplified version for memory estimation.
 */
extern "C" void matter_zigbee_light_sync(bool on_off, uint8_t level) {
  // In a full implementation, this would update Matter attributes
  // For now, just log for memory estimation purposes
  LOG_DBG("Light sync: on_off=%d, level=%d", on_off, level);
}

#endif /* CONFIG_CHIP */

/**
 * @brief Update Matter on/off attribute from Zigbee state
 */
extern "C" void matter_update_onoff(bool on) {
  LOG_DBG("Updating Matter on/off to %d", on);
  // For memory estimation, we skip the actual cluster update
  // In full implementation:
  // chip::app::Clusters::OnOff::Attributes::OnOff::Set(MATTER_LIGHT_ENDPOINT,
  // on);
}

/**
 * @brief Update Matter level control attribute from Zigbee state
 */
extern "C" void matter_update_level(uint8_t level) {
  LOG_DBG("Updating Matter level to %d", level);
  // For memory estimation, we skip the actual cluster update
  // In full implementation:
  // chip::app::Clusters::LevelControl::Attributes::CurrentLevel::Set(MATTER_LIGHT_ENDPOINT,
  // level);
}
```
